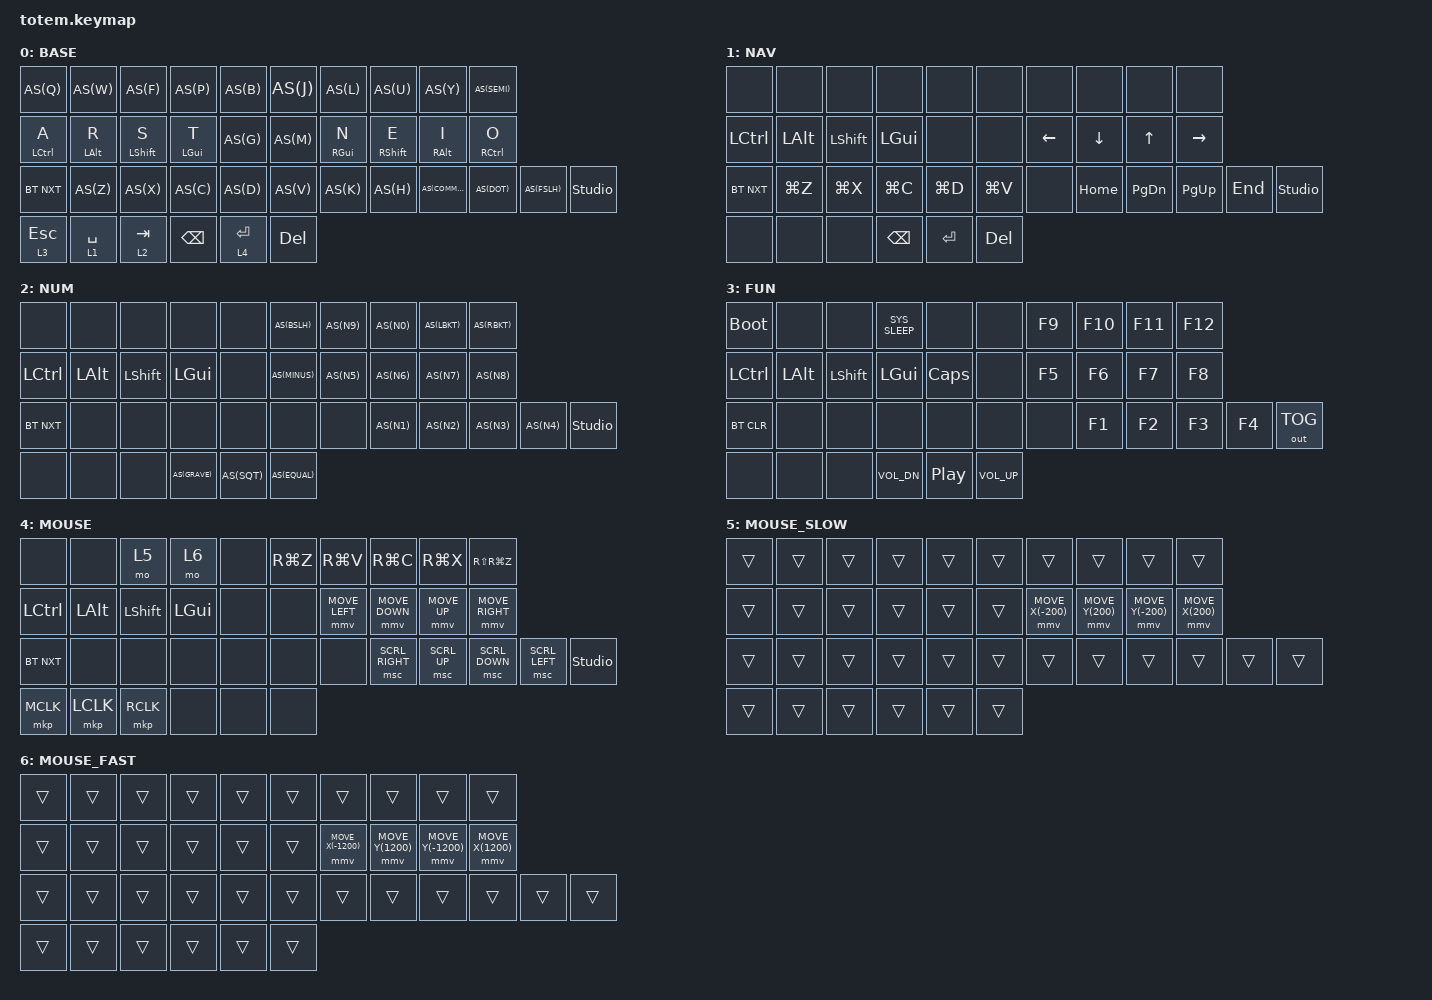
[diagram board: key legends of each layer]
// Generated by scripts/convert_qmk.py. See MIGRATION.md for behavioral differences.
#include <behaviors.dtsi>
#include <dt-bindings/zmk/keys.h>
#include <dt-bindings/zmk/bt.h>
#include <dt-bindings/zmk/outputs.h>
#include <dt-bindings/zmk/pointing.h>
#define AS(k) &as LS(k) k

&lt {
    tapping-term-ms = <175>;
    flavor = "hold-preferred";
    retro-tap;
};

/ {
    behaviors {
        as: auto_shift {
            compatible = "zmk,behavior-hold-tap";
            #binding-cells = <2>;
            bindings = <&kp>, <&kp>;
            flavor = "tap-preferred";
            tapping-term-ms = <175>;
            quick-tap-ms = <0>;
            display-name = "Auto Shift 175ms";
        };
        hml: home_row_l {
            compatible = "zmk,behavior-hold-tap";
            #binding-cells = <2>;
            bindings = <&kp>, <&kp>;
            flavor = "hold-preferred";
            tapping-term-ms = <175>;
            retro-tap;
            retro-shift-ms = <500>;
            hold-trigger-key-positions = <0 1 2 3 4 5 6 7 8 9 14 15 16 17 18 19 20 21 22 23 24 25 26 27 28 29 30 31 32 33 34 35 36 37>;
            display-name = "Home row L";
        };
        hmr: home_row_r {
            compatible = "zmk,behavior-hold-tap";
            #binding-cells = <2>;
            bindings = <&kp>, <&kp>;
            flavor = "hold-preferred";
            tapping-term-ms = <175>;
            retro-tap;
            retro-shift-ms = <500>;
            hold-trigger-key-positions = <0 1 2 3 4 5 6 7 8 9 10 11 12 13 14 15 20 21 22 23 24 25 26 27 28 29 30 31 32 33 34 35 36 37>;
            display-name = "Home row R";
        };
    };
    keymap {
        compatible = "zmk,keymap";
        base {
            display-name = "BASE";
            bindings = <
                AS(Q)                  AS(W)                  AS(F)                  AS(P)                  AS(B)                  AS(J)                  AS(L)                  AS(U)                  AS(Y)                  AS(SEMI)
                &hml LCTRL A           &hml LALT R            &hml LSHFT S           &hml LGUI T            AS(G)                  AS(M)                  &hmr RGUI N            &hmr RSHFT E           &hmr RALT I            &hmr RCTRL O
                &bt BT_NXT             AS(Z)                  AS(X)                  AS(C)                  AS(D)                  AS(V)                  AS(K)                  AS(H)                  AS(COMMA)              AS(DOT)                AS(FSLH)               &studio_unlock
                &lt 3 ESC              &lt 1 SPACE            &lt 2 TAB              &kp BSPC               &lt 4 RET              &kp DEL
            >;
        };
        nav {
            display-name = "NAV";
            bindings = <
                &none                  &none                  &none                  &none                  &none                  &none                  &none                  &none                  &none                  &none
                &kp LCTRL              &kp LALT               &kp LSHFT              &kp LGUI               &none                  &none                  &kp LEFT               &kp DOWN               &kp UP                 &kp RIGHT
                &bt BT_NXT             &kp LG(Z)              &kp LG(X)              &kp LG(C)              &kp LG(D)              &kp LG(V)              &none                  &kp HOME               &kp PG_DN              &kp PG_UP              &kp END                &studio_unlock
                &none                  &none                  &none                  &kp BSPC               &kp RET                &kp DEL
            >;
        };
        num {
            display-name = "NUM";
            bindings = <
                &none                  &none                  &none                  &none                  &none                  AS(BSLH)               AS(N9)                 AS(N0)                 AS(LBKT)               AS(RBKT)
                &kp LCTRL              &kp LALT               &kp LSHFT              &kp LGUI               &none                  AS(MINUS)              AS(N5)                 AS(N6)                 AS(N7)                 AS(N8)
                &bt BT_NXT             &none                  &none                  &none                  &none                  &none                  &none                  AS(N1)                 AS(N2)                 AS(N3)                 AS(N4)                 &studio_unlock
                &none                  &none                  &none                  AS(GRAVE)              AS(SQT)                AS(EQUAL)
            >;
        };
        fun {
            display-name = "FUN";
            bindings = <
                &bootloader            &none                  &none                  &kp SYS_SLEEP          &none                  &none                  &kp F9                 &kp F10                &kp F11                &kp F12
                &kp LCTRL              &kp LALT               &kp LSHFT              &kp LGUI               &kp CAPS               &none                  &kp F5                 &kp F6                 &kp F7                 &kp F8
                &bt BT_CLR             &none                  &none                  &none                  &none                  &none                  &none                  &kp F1                 &kp F2                 &kp F3                 &kp F4                 &out OUT_TOG
                &none                  &none                  &none                  &kp C_VOL_DN           &kp C_PP               &kp C_VOL_UP
            >;
        };
        mouse {
            display-name = "MOUSE";
            bindings = <
                &none                  &none                  &mo 5                  &mo 6                  &none                  &kp RG(Z)              &kp RG(V)              &kp RG(C)              &kp RG(X)              &kp RS(RG(Z))
                &kp LCTRL              &kp LALT               &kp LSHFT              &kp LGUI               &none                  &none                  &mmv MOVE_LEFT         &mmv MOVE_DOWN         &mmv MOVE_UP           &mmv MOVE_RIGHT
                &bt BT_NXT             &none                  &none                  &none                  &none                  &none                  &none                  &msc SCRL_RIGHT        &msc SCRL_UP           &msc SCRL_DOWN         &msc SCRL_LEFT         &studio_unlock
                &mkp MCLK              &mkp LCLK              &mkp RCLK              &none                  &none                  &none
            >;
        };
        mouse_slow {
            display-name = "MOUSE_SLOW";
            bindings = <
                &trans                 &trans                 &trans                 &trans                 &trans                 &trans                 &trans                 &trans                 &trans                 &trans
                &trans                 &trans                 &trans                 &trans                 &trans                 &trans                 &mmv MOVE_X(-200)      &mmv MOVE_Y(200)       &mmv MOVE_Y(-200)      &mmv MOVE_X(200)
                &trans                 &trans                 &trans                 &trans                 &trans                 &trans                 &trans                 &trans                 &trans                 &trans                 &trans                 &trans
                &trans                 &trans                 &trans                 &trans                 &trans                 &trans
            >;
        };
        mouse_fast {
            display-name = "MOUSE_FAST";
            bindings = <
                &trans                 &trans                 &trans                 &trans                 &trans                 &trans                 &trans                 &trans                 &trans                 &trans
                &trans                 &trans                 &trans                 &trans                 &trans                 &trans                 &mmv MOVE_X(-1200)     &mmv MOVE_Y(1200)      &mmv MOVE_Y(-1200)     &mmv MOVE_X(1200)
                &trans                 &trans                 &trans                 &trans                 &trans                 &trans                 &trans                 &trans                 &trans                 &trans                 &trans                 &trans
                &trans                 &trans                 &trans                 &trans                 &trans                 &trans
            >;
        };
    };
};
